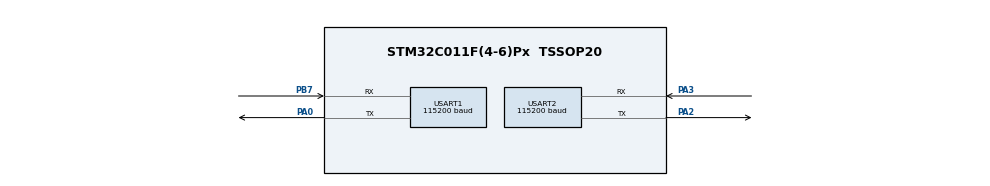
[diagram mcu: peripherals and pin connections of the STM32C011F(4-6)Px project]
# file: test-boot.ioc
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Mcu.Family=STM32C0
Mcu.Name=STM32C011F(4-6)Px
Mcu.Package=TSSOP20
NVIC.TimeBase=None
PA0.GPIO_ModeDefaultPP=GPIO_MODE_AF_PP
PA0.Mode=Asynchronous
PA0.Signal=USART1_TX
PA2.GPIO_ModeDefaultPP=GPIO_MODE_AF_PP
PA2.Mode=Asynchronous
PA2.Signal=USART2_TX
PA3.Mode=Asynchronous
PA3.Signal=USART2_RX
PB7.Mode=Asynchronous
PB7.Signal=USART1_RX
ProjectManager.HeapSize=0x000
ProjectManager.StackSize=0x500
ProjectManager.TargetToolchain=STM32CubeIDE
RCC.ADCFreq_Value=48000000
RCC.AHBFreq_Value=48000000
RCC.CortexFreq_Value=48000000
RCC.EXTERNAL_CLOCK_VALUE=12288000
RCC.HCLKFreq_Value=48000000
RCC.HSE_VALUE=20000000
RCC.HSISYSCLKDivider=RCC_HSI_DIV1
RCC.HSI_VALUE=48000000
RCC.LSE_VALUE=32768
RCC.SYSCLKFreq_VALUE=48000000
USART1.BaudRate=115200
USART1.FIFOMode=FIFOMODE_DISABLE
USART1.OverrunDisableParam=ADVFEATURE_OVERRUN_DISABLE
USART1.StopBits=STOPBITS_2
USART1.VirtualMode-Asynchronous=VM_ASYNC
USART2.BaudRate=115200
USART2.OverrunDisableParam=ADVFEATURE_OVERRUN_DISABLE
USART2.StopBits=STOPBITS_2
USART2.VirtualMode-Asynchronous=VM_ASYNC
VP_CRC_VS_CRC.Mode=CRC_Activate
VP_SYS_VS_None.Mode=None
board=custom

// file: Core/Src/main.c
/* USER CODE BEGIN Header */
/**
  ******************************************************************************
  * @file           : main.c
  * @brief          : Main program body
  ******************************************************************************
  * @attention
  *
  * Copyright (c) 2026 STMicroelectronics.
  * All rights reserved.
  *
  * This software is licensed under terms that can be found in the LICENSE file
  * in the root directory of this software component.
  * If no LICENSE file comes with this software, it is provided AS-IS.
  *
  ******************************************************************************
  */
/* USER CODE END Header */
#include "main.h"

CRC_HandleTypeDef hcrc;

void SystemClock_Config(void);
static void MX_GPIO_Init(void);
static void MX_USART1_UART_Init(void);
static void MX_USART2_UART_Init(void);
static void MX_CRC_Init(void);

/* USER CODE BEGIN 0 */

HAL_StatusTypeDef HAL_InitTick(uint32_t TickPriority)
{
  return HAL_OK;
}

/* USER CODE END 0 */

int main(void)
{

  __disable_irq();

  /* MCU Configuration--------------------------------------------------------*/

  /* Reset of all peripherals, Initializes the Flash interface and the Systick. */
  HAL_Init();

  /* Configure the system clock */
  SystemClock_Config();

  /* Initialize all configured peripherals */
  MX_GPIO_Init();
  MX_USART1_UART_Init();
  MX_USART2_UART_Init();
  MX_CRC_Init();
  __disable_irq();

  /* Infinite loop */
  /* USER CODE BEGIN WHILE */
  while (1)
  {
    void uartPoll(USART_TypeDef *uart0, USART_TypeDef *uart1, USART_TypeDef *uart2, USART_TypeDef *uart3);
    uartPoll(USART1, USART2, NULL, NULL);
    /* USER CODE END WHILE */

  }
}

void SystemClock_Config(void)
{

  LL_FLASH_SetLatency(LL_FLASH_LATENCY_1);

  /* HSI configuration and activation */
  LL_RCC_HSI_Enable();
  while(LL_RCC_HSI_IsReady() != 1)
  {
  }

  LL_RCC_HSI_SetCalibTrimming(64);
  LL_RCC_SetHSIDiv(LL_RCC_HSI_DIV_1);
  /* Set AHB prescaler*/
  LL_RCC_SetAHBPrescaler(LL_RCC_HCLK_DIV_1);

  /* Sysclk activation on the HSI */
  LL_RCC_SetSysClkSource(LL_RCC_SYS_CLKSOURCE_HSI);
  while(LL_RCC_GetSysClkSource() != LL_RCC_SYS_CLKSOURCE_STATUS_HSI)
  {
  }

  /* Set APB1 prescaler*/
  LL_RCC_SetAPB1Prescaler(LL_RCC_APB1_DIV_1);
  /* Update CMSIS variable (which can be updated also through SystemCoreClockUpdate function) */
  LL_SetSystemCoreClock(48000000);

   /* Update the time base */
  if (HAL_InitTick (TICK_INT_PRIORITY) != HAL_OK)
  {
    Error_Handler();
  }
}

static void MX_CRC_Init(void)
{

  /* USER CODE BEGIN CRC_Init 0 */
#if 0
  /* USER CODE END CRC_Init 0 */

  hcrc.Instance = CRC;
  hcrc.Init.DefaultPolynomialUse = DEFAULT_POLYNOMIAL_ENABLE;
  hcrc.Init.DefaultInitValueUse = DEFAULT_INIT_VALUE_ENABLE;
  hcrc.Init.InputDataInversionMode = CRC_INPUTDATA_INVERSION_NONE;
  hcrc.Init.OutputDataInversionMode = CRC_OUTPUTDATA_INVERSION_DISABLE;
  hcrc.InputDataFormat = CRC_INPUTDATA_FORMAT_BYTES;
  if (HAL_CRC_Init(&hcrc) != HAL_OK)
  {
    Error_Handler();
  }
  /* USER CODE BEGIN CRC_Init 2 */
#else
  __HAL_RCC_CRC_CLK_ENABLE();
#endif
  /* USER CODE END CRC_Init 2 */

}

static void MX_USART1_UART_Init(void)
{

  LL_USART_InitTypeDef USART_InitStruct = {0};

  LL_GPIO_InitTypeDef GPIO_InitStruct = {0};

  LL_RCC_SetUSARTClockSource(LL_RCC_USART1_CLKSOURCE_PCLK1);

  /* Peripheral clock enable */
  LL_APB2_GRP1_EnableClock(LL_APB2_GRP1_PERIPH_USART1);

  LL_IOP_GRP1_EnableClock(LL_IOP_GRP1_PERIPH_GPIOB);
  LL_IOP_GRP1_EnableClock(LL_IOP_GRP1_PERIPH_GPIOA);
  /**USART1 GPIO Configuration
  PB7   ------> USART1_RX
  PA0   ------> USART1_TX
  */
  GPIO_InitStruct.Pin = LL_GPIO_PIN_7;
  GPIO_InitStruct.Mode = LL_GPIO_MODE_ALTERNATE;
  GPIO_InitStruct.Speed = LL_GPIO_SPEED_FREQ_LOW;
  GPIO_InitStruct.OutputType = (PORT0_OC ? LL_GPIO_OUTPUT_OPENDRAIN : LL_GPIO_OUTPUT_PUSHPULL);
  GPIO_InitStruct.Pull = LL_GPIO_PULL_NO;
  GPIO_InitStruct.Alternate = LL_GPIO_AF_0;
  LL_GPIO_Init(GPIOB, &GPIO_InitStruct);

  GPIO_InitStruct.Pin = LL_GPIO_PIN_0;
  GPIO_InitStruct.Mode = LL_GPIO_MODE_ALTERNATE;
  GPIO_InitStruct.Speed = LL_GPIO_SPEED_FREQ_LOW;
  GPIO_InitStruct.OutputType = LL_GPIO_OUTPUT_PUSHPULL;
  GPIO_InitStruct.Pull = LL_GPIO_PULL_NO;
  GPIO_InitStruct.Alternate = LL_GPIO_AF_4;
  LL_GPIO_Init(GPIOA, &GPIO_InitStruct);

  USART_InitStruct.PrescalerValue = LL_USART_PRESCALER_DIV1;
  USART_InitStruct.BaudRate = PORT0_BAUDRATE;
  USART_InitStruct.DataWidth = LL_USART_DATAWIDTH_8B;
  USART_InitStruct.StopBits = LL_USART_STOPBITS_2;
  USART_InitStruct.Parity = LL_USART_PARITY_NONE;
  USART_InitStruct.TransferDirection = LL_USART_DIRECTION_TX_RX;
  USART_InitStruct.HardwareFlowControl = LL_USART_HWCONTROL_NONE;
  USART_InitStruct.OverSampling = LL_USART_OVERSAMPLING_16;
  LL_USART_Init(USART1, &USART_InitStruct);
  LL_USART_SetTXFIFOThreshold(USART1, LL_USART_FIFOTHRESHOLD_1_8);
  LL_USART_SetRXFIFOThreshold(USART1, LL_USART_FIFOTHRESHOLD_1_8);
  LL_USART_DisableFIFO(USART1);
  LL_USART_DisableOverrunDetect(USART1);
  LL_USART_ConfigAsyncMode(USART1);

  LL_USART_Enable(USART1);

  /* Polling USART1 initialisation */
  while((!(LL_USART_IsActiveFlag_TEACK(USART1))) || (!(LL_USART_IsActiveFlag_REACK(USART1))))
  {
  }

}

static void MX_USART2_UART_Init(void)
{

  LL_USART_InitTypeDef USART_InitStruct = {0};

  LL_GPIO_InitTypeDef GPIO_InitStruct = {0};

  /* Peripheral clock enable */
  LL_APB1_GRP1_EnableClock(LL_APB1_GRP1_PERIPH_USART2);

  LL_IOP_GRP1_EnableClock(LL_IOP_GRP1_PERIPH_GPIOA);
  /**USART2 GPIO Configuration
  PA2   ------> USART2_TX
  PA3   ------> USART2_RX
  */
  GPIO_InitStruct.Pin = LL_GPIO_PIN_2;
  GPIO_InitStruct.Mode = LL_GPIO_MODE_ALTERNATE;
  GPIO_InitStruct.Speed = LL_GPIO_SPEED_FREQ_LOW;
  GPIO_InitStruct.OutputType = (PORT1_OC ? LL_GPIO_OUTPUT_OPENDRAIN : LL_GPIO_OUTPUT_PUSHPULL);
  GPIO_InitStruct.Pull = LL_GPIO_PULL_NO;
  GPIO_InitStruct.Alternate = LL_GPIO_AF_1;
  LL_GPIO_Init(GPIOA, &GPIO_InitStruct);

  GPIO_InitStruct.Pin = LL_GPIO_PIN_3;
  GPIO_InitStruct.Mode = LL_GPIO_MODE_ALTERNATE;
  GPIO_InitStruct.Speed = LL_GPIO_SPEED_FREQ_LOW;
  GPIO_InitStruct.OutputType = LL_GPIO_OUTPUT_PUSHPULL;
  GPIO_InitStruct.Pull = LL_GPIO_PULL_NO;
  GPIO_InitStruct.Alternate = LL_GPIO_AF_1;
  LL_GPIO_Init(GPIOA, &GPIO_InitStruct);

  USART_InitStruct.PrescalerValue = LL_USART_PRESCALER_DIV1;
  USART_InitStruct.BaudRate = PORT1_BAUDRATE;
  USART_InitStruct.DataWidth = LL_USART_DATAWIDTH_8B;
  USART_InitStruct.StopBits = LL_USART_STOPBITS_2;
  USART_InitStruct.Parity = LL_USART_PARITY_NONE;
  USART_InitStruct.TransferDirection = LL_USART_DIRECTION_TX_RX;
  USART_InitStruct.HardwareFlowControl = LL_USART_HWCONTROL_NONE;
  USART_InitStruct.OverSampling = LL_USART_OVERSAMPLING_16;
  LL_USART_Init(USART2, &USART_InitStruct);
  LL_USART_DisableOverrunDetect(USART2);
  LL_USART_ConfigAsyncMode(USART2);

  LL_USART_Enable(USART2);

  /* Polling USART2 initialisation */
  while((!(LL_USART_IsActiveFlag_TEACK(USART2))) || (!(LL_USART_IsActiveFlag_REACK(USART2))))
  {
  }

}

static void MX_GPIO_Init(void)
{

  /* GPIO Ports Clock Enable */
  LL_IOP_GRP1_EnableClock(LL_IOP_GRP1_PERIPH_GPIOB);
  LL_IOP_GRP1_EnableClock(LL_IOP_GRP1_PERIPH_GPIOA);

}

void Error_Handler(void)
{
  __disable_irq();
  while (1)
  {
  }
}
